# ESP32C3 register map
File version: 1.0
CPU: RISC-V RV32IMC single-core 1, little endian, no MPU, FPU, 3 interrupt priority bits
Registers are 32-bit, read-write, reset 0x0 unless marked. A register's access mark holds for its fields unless they carry their own. Offsets are from the block's base; [hi:lo] are bit positions.

## APB_SARADC
Base 0x60040000
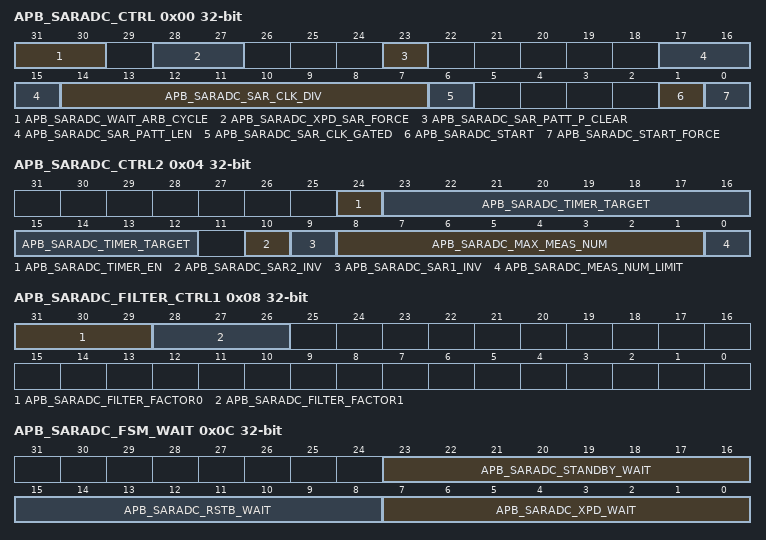
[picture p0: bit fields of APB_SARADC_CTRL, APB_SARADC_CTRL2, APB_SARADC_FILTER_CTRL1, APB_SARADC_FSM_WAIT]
0x00 APB_SARADC_CTRL
  [31:30] APB_SARADC_WAIT_ARB_CYCLE, [28:27] APB_SARADC_XPD_SAR_FORCE, [23] APB_SARADC_SAR_PATT_P_CLEAR, [17:15] APB_SARADC_SAR_PATT_LEN, [14:7] APB_SARADC_SAR_CLK_DIV, [6] APB_SARADC_SAR_CLK_GATED, [1] APB_SARADC_START, [0] APB_SARADC_START_FORCE
0x04 APB_SARADC_CTRL2
  [24] APB_SARADC_TIMER_EN, [23:12] APB_SARADC_TIMER_TARGET, [10] APB_SARADC_SAR2_INV, [9] APB_SARADC_SAR1_INV, [8:1] APB_SARADC_MAX_MEAS_NUM, [0] APB_SARADC_MEAS_NUM_LIMIT
0x08 APB_SARADC_FILTER_CTRL1
  [31:29] APB_SARADC_FILTER_FACTOR0, [28:26] APB_SARADC_FILTER_FACTOR1
0x0C APB_SARADC_FSM_WAIT
  [23:16] APB_SARADC_STANDBY_WAIT, [15:8] APB_SARADC_RSTB_WAIT, [7:0] APB_SARADC_XPD_WAIT
0x10 APB_SARADC_SAR1_STATUS ro
0x14 APB_SARADC_SAR2_STATUS ro
0x18 APB_SARADC_SAR_PATT_TAB1
  [23:0] APB_SARADC_SAR_PATT_TAB1
0x1C APB_SARADC_SAR_PATT_TAB2
  [23:0] APB_SARADC_SAR_PATT_TAB2
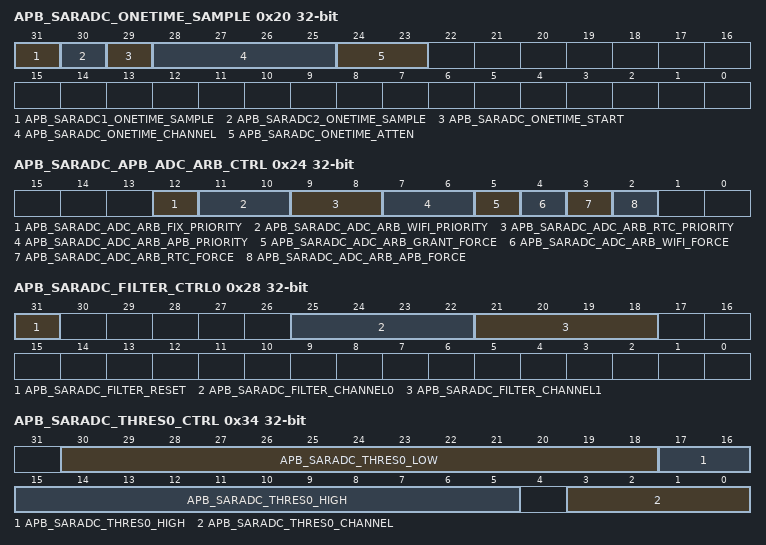
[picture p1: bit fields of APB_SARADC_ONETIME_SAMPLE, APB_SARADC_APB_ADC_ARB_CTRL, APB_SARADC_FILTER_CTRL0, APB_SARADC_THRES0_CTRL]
0x20 APB_SARADC_ONETIME_SAMPLE
  [31] APB_SARADC1_ONETIME_SAMPLE, [30] APB_SARADC2_ONETIME_SAMPLE, [29] APB_SARADC_ONETIME_START, [28:25] APB_SARADC_ONETIME_CHANNEL, [24:23] APB_SARADC_ONETIME_ATTEN
0x24 APB_SARADC_APB_ADC_ARB_CTRL
  [12] APB_SARADC_ADC_ARB_FIX_PRIORITY, [11:10] APB_SARADC_ADC_ARB_WIFI_PRIORITY, [9:8] APB_SARADC_ADC_ARB_RTC_PRIORITY, [7:6] APB_SARADC_ADC_ARB_APB_PRIORITY, [5] APB_SARADC_ADC_ARB_GRANT_FORCE, [4] APB_SARADC_ADC_ARB_WIFI_FORCE, [3] APB_SARADC_ADC_ARB_RTC_FORCE, [2] APB_SARADC_ADC_ARB_APB_FORCE
0x28 APB_SARADC_FILTER_CTRL0
  [31] APB_SARADC_FILTER_RESET, [25:22] APB_SARADC_FILTER_CHANNEL0, [21:18] APB_SARADC_FILTER_CHANNEL1
0x2C APB_SARADC_1_DATA_STATUS ro
  [16:0] APB_SARADC_ADC1_DATA
0x30 APB_SARADC_2_DATA_STATUS ro
  [16:0] APB_SARADC_ADC2_DATA
0x34 APB_SARADC_THRES0_CTRL
  [30:18] APB_SARADC_THRES0_LOW, [17:5] APB_SARADC_THRES0_HIGH, [3:0] APB_SARADC_THRES0_CHANNEL
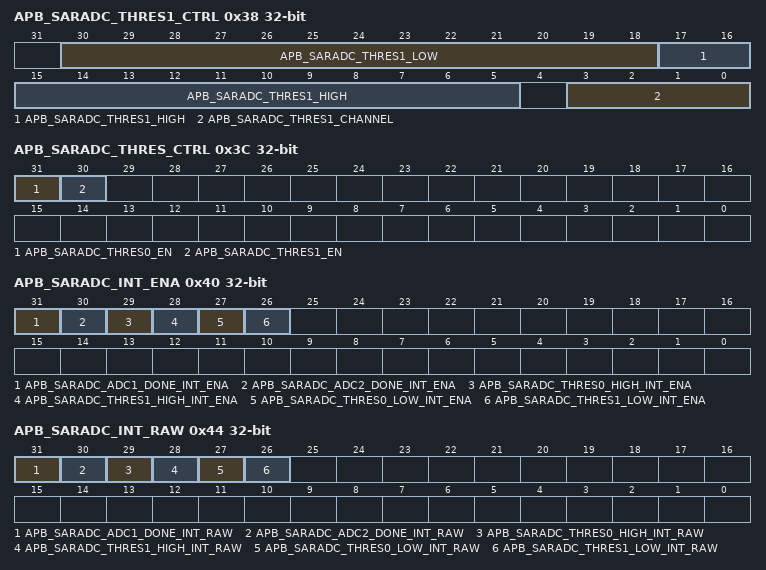
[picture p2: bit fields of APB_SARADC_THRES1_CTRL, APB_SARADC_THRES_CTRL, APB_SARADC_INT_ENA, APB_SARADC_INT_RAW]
0x38 APB_SARADC_THRES1_CTRL
  [30:18] APB_SARADC_THRES1_LOW, [17:5] APB_SARADC_THRES1_HIGH, [3:0] APB_SARADC_THRES1_CHANNEL
0x3C APB_SARADC_THRES_CTRL
  [31] APB_SARADC_THRES0_EN, [30] APB_SARADC_THRES1_EN
0x40 APB_SARADC_INT_ENA
  [31] APB_SARADC_ADC1_DONE_INT_ENA, [30] APB_SARADC_ADC2_DONE_INT_ENA, [29] APB_SARADC_THRES0_HIGH_INT_ENA, [28] APB_SARADC_THRES1_HIGH_INT_ENA, [27] APB_SARADC_THRES0_LOW_INT_ENA, [26] APB_SARADC_THRES1_LOW_INT_ENA
0x44 APB_SARADC_INT_RAW ro
  [31] APB_SARADC_ADC1_DONE_INT_RAW, [30] APB_SARADC_ADC2_DONE_INT_RAW, [29] APB_SARADC_THRES0_HIGH_INT_RAW, [28] APB_SARADC_THRES1_HIGH_INT_RAW, [27] APB_SARADC_THRES0_LOW_INT_RAW, [26] APB_SARADC_THRES1_LOW_INT_RAW
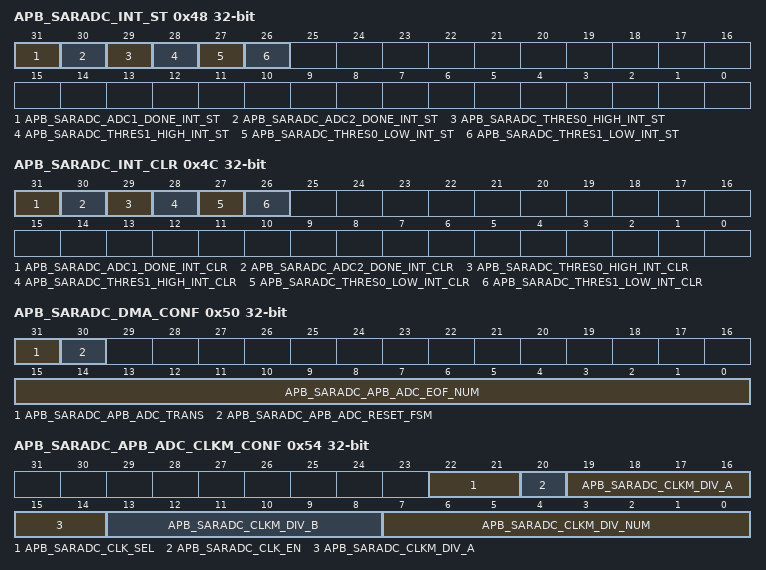
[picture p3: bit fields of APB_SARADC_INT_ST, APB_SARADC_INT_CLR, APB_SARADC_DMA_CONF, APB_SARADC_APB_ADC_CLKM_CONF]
0x48 APB_SARADC_INT_ST ro
  [31] APB_SARADC_ADC1_DONE_INT_ST, [30] APB_SARADC_ADC2_DONE_INT_ST, [29] APB_SARADC_THRES0_HIGH_INT_ST, [28] APB_SARADC_THRES1_HIGH_INT_ST, [27] APB_SARADC_THRES0_LOW_INT_ST, [26] APB_SARADC_THRES1_LOW_INT_ST
0x4C APB_SARADC_INT_CLR wo
  [31] APB_SARADC_ADC1_DONE_INT_CLR, [30] APB_SARADC_ADC2_DONE_INT_CLR, [29] APB_SARADC_THRES0_HIGH_INT_CLR, [28] APB_SARADC_THRES1_HIGH_INT_CLR, [27] APB_SARADC_THRES0_LOW_INT_CLR, [26] APB_SARADC_THRES1_LOW_INT_CLR
0x50 APB_SARADC_DMA_CONF
  [31] APB_SARADC_APB_ADC_TRANS, [30] APB_SARADC_APB_ADC_RESET_FSM, [15:0] APB_SARADC_APB_ADC_EOF_NUM
0x54 APB_SARADC_APB_ADC_CLKM_CONF
  [22:21] APB_SARADC_CLK_SEL, [20] APB_SARADC_CLK_EN, [19:14] APB_SARADC_CLKM_DIV_A, [13:8] APB_SARADC_CLKM_DIV_B, [7:0] APB_SARADC_CLKM_DIV_NUM
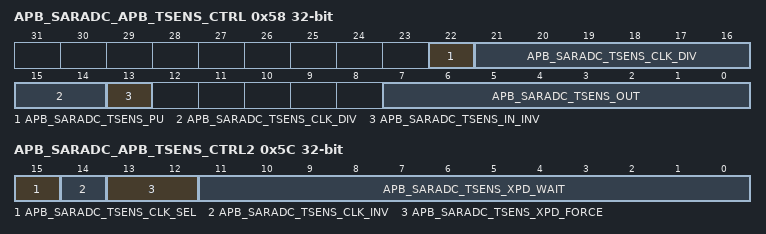
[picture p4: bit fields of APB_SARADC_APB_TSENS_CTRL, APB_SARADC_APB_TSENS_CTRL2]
0x58 APB_SARADC_APB_TSENS_CTRL access per field
  [22] APB_SARADC_TSENS_PU rw, [21:14] APB_SARADC_TSENS_CLK_DIV rw, [13] APB_SARADC_TSENS_IN_INV rw, [7:0] APB_SARADC_TSENS_OUT ro
0x5C APB_SARADC_APB_TSENS_CTRL2
  [15] APB_SARADC_TSENS_CLK_SEL, [14] APB_SARADC_TSENS_CLK_INV, [13:12] APB_SARADC_TSENS_XPD_FORCE, [11:0] APB_SARADC_TSENS_XPD_WAIT
0x60 APB_SARADC_CALI
  [16:0] APB_SARADC_CALI_CFG
0x3FC APB_SARADC_APB_CTRL_DATE
  [31:0] APB_SARADC_DATE
